# KM1M7CF15 register map
Vendor: Nuvoton Technology Corporation Japan; Series: KM1M7CF; File version: 1.0.3
CPU: CM7 r1p2, little endian, MPU, FPU, double-precision FPU, I-cache, D-cache, ITCM, DTCM, 4 interrupt priority bits
Registers are 32-bit, read-write, no defined reset value unless marked. A register's access mark holds for its fields unless they carry their own. Offsets are from the block's base; [hi:lo] are bit positions; {n}, {i} and the like mark numbered series.

## SYTM — Clock Generator
Base 0x40000000
0x00 SYS_PDID ro — Part Device ID Register
  [31:0] PDID — LSI product number ID
0x08 SYS_DID ro — Device ID Register
  [31:0] DID — Device ID
0x0C SYS_CID ro — Company ID Register
  [31:0] CID — Company ID
{0x10+4i} SYS_UID{i} ro (i=0..3) — U{i}ique ID n Register
  [31:0] UID — Uniqued data for each chip can be read.
{0x20+4i} SYS_UCID{i} ro (i=0..3) — U{i}ique Company ID n Register
  [31:0] UID — "0xFFFFFFFF" is always read out.
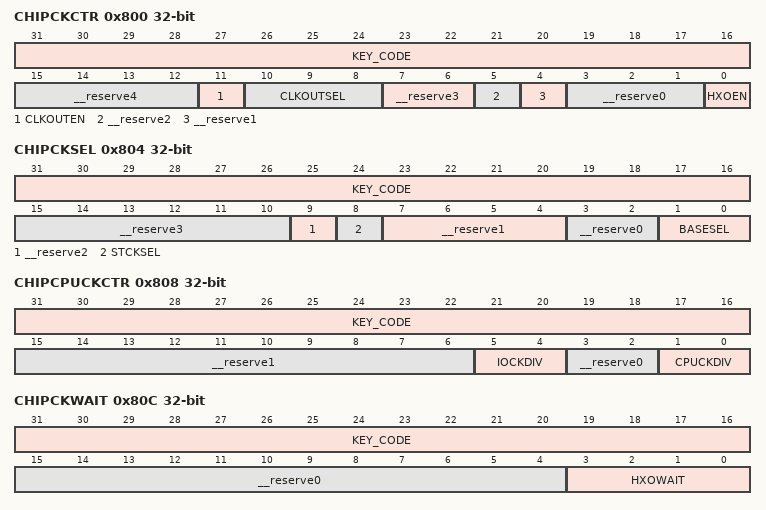
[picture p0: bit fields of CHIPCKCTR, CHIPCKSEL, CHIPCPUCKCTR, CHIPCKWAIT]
0x800 CHIPCKCTR access per field — Clock Control Register
  [31:16] KEY_CODE wo — Write enable code
  [15:12] __reserve4 rw — This bit must be set to "0".
  [11] CLKOUTEN rw — Internal clock output function
  [10:8] CLKOUTSEL rw — Output clock selection when the internal clock output function is enabled
  [7:6] __reserve3 rw — This bit must be set to "0".
  [5] __reserve2 ro — "0" is always read out.
  [4] __reserve1 rw — This bit must be set to "0".
  [3:1] __reserve0 rw — This bit must be set to "１".
  [0] HXOEN rw — External high-speed oscillation (HXO)
0x804 CHIPCKSEL access per field — Clock Selection Register
  [31:16] KEY_CODE wo — Write enable code
  [15:10] __reserve3 ro — "0" is always read out.
  [9] __reserve2 rw — This bit must be set to "0".
  [8] STCKSEL rw — Clock source selection for Systick
  [7:4] __reserve1 ro — "0" is always read out.
  [3:2] __reserve0 rw — This bit must be set to "0".
  [1:0] BASESEL rw — Clock source selection for the base clock (BASECLK)
0x808 CHIPCPUCKCTR access per field — CPU Clock Control Register
  [31:16] KEY_CODE wo — Write enable code
  [15:6] __reserve1 ro — "0" is always read out.
  [5:4] IOCKDIV rw — Setting of IOCLK division ratio for CPUCLK
  [3:2] __reserve0 ro — "0" is always read out.
  [1:0] CPUCKDIV rw — Setting of CPUCLK division ratio for BASECLK
0x80C CHIPCKWAIT access per field — Clock Oscillation Stabilization Wait Register
  [31:16] KEY_CODE wo — Write enable code
  [15:4] __reserve0 ro — "0" is always read out.
  [3:0] HXOWAIT rw — HXO oscillation stabilization wait cycle setting
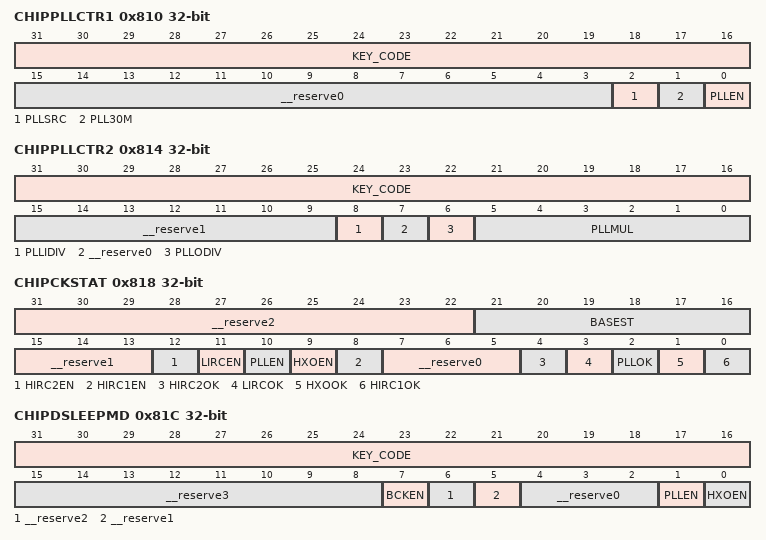
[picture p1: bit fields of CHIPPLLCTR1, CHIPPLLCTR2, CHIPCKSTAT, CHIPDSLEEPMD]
0x810 CHIPPLLCTR1 access per field — PLL Control Register 1
  [31:16] KEY_CODE wo — Write enable code
  [15:3] __reserve0 ro — "0" is always read out.
  [2] PLLSRC rw — Selection of the reference clock to be multiplied by PLL
  [1] PLL30M rw — PLL clock output control for Power Control PWM using High-Resolution output
  [0] PLLEN rw — PLL function
0x814 CHIPPLLCTR2 access per field — PLL Control Register 2
  [31:16] KEY_CODE wo — Write enable code
  [15:9] __reserve1 ro — "0" is always read out.
  [8] PLLIDIV rw — PLL input clock division ratio setting
  [7] __reserve0 ro — "0" is always read out.
  [6] PLLODIV rw — PLL output clock division ratio setting
  [5:0] PLLMUL rw — PLL multiplier value setting
0x818 CHIPCKSTAT ro — Clock Status Register
  [31:22] __reserve2 — "0" is always read out.
  [21:16] BASEST — State of each clock selection to BASECLK (0: not selected, 1: selected)
  [15:13] __reserve1 — "0" is always read out.
  [12] HIRC2EN — Internal high-speed oscillation 2 (HIRC2) state
  [11] LIRCEN — Internal low-speed oscillation (LIRC) state
  [10] PLLEN — PLL function state
  [9] HXOEN — External high-speed oscillation (HXO) state
  [8] HIRC1EN — Internal high-speed oscillation 1 (HIRC1) state
  [7:5] __reserve0 — "0" is always read out.
  [4] HIRC2OK — Internal high-speed oscillation 2 (HIRC2) stabilization status
  [3] LIRCOK — Internal low-speed oscillation (LIRC) stabilization status
  [2] PLLOK — PLL stabilization status
  [1] HXOOK — External high-speed oscillation (HXO) stabilization status
  [0] HIRC1OK — Internal high-speed oscillation 1(HIRC1) stabilization status
0x81C CHIPDSLEEPMD access per field — DEEPSLEEP Mode Control Register
  [31:16] KEY_CODE wo — Write enable code
  [15:8] __reserve3 ro — "0" is always read out.
  [7] BCKEN rw — Set BASECLK for DEEPSLEEP
  [6] __reserve2 ro — "0" is always read out.
  [5] __reserve1 rw — This bit must be set to "0".
  [4:2] __reserve0 ro — "1" is always read out.
  [1] PLLEN rw — Set PLL ON/OFF for DEEPSLEEP
  [0] HXOEN rw — Set external oscillation (HXO) ON/OFF for DEEPSLEEP
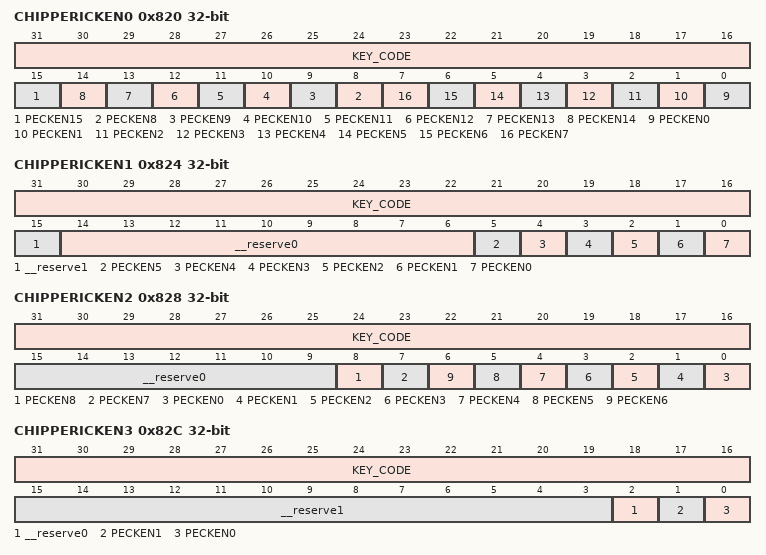
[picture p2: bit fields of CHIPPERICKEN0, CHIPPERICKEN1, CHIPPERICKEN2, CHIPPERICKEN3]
0x820 CHIPPERICKEN0 access per field — Peripheral Clock Enable Register 0
  [31:16] KEY_CODE wo — Write enable code
  [15] PECKEN15 rw — Clock supply to Multi Feedback Assist
  [n] PECKEN{n} rw (n=8..14) — Clock supply to Timer {2n-16} and {2n-15}
  [n] PECKEN{n} rw (n=0..7) — Clock supply to GPWM{n}
0x824 CHIPPERICKEN1 access per field — Peripheral Clock Enable Register 1
  [31:16] KEY_CODE wo — Write enable code
  [15] __reserve1 rw — This bit must be set to "0".
  [14:6] __reserve0 ro — "0" is always read out.
  [5] PECKEN5 rw — Clock supply to DMA controller
  [4] PECKEN4 rw — Clock supply to RTC
  [3] PECKEN3 rw — Clock supply to D/A Converter
  [2] PECKEN2 rw — Clock supply to A/D 2
  [1] PECKEN1 rw — Clock supply to A/D 1
  [0] PECKEN0 rw — Clock supply to A/D 0
0x828 CHIPPERICKEN2 access per field — Peripheral Clock Enable Register 2
  [31:16] KEY_CODE wo — Write enable code
  [15:9] __reserve0 ro — "0" is always read out.
  [8] PECKEN8 rw — Clock supply to CAN FD controller
  [7] PECKEN7 rw — Clock supply to SMBus/IIC Interface
  [n] PECKEN{n} rw (n=0..6) — Clock supply to serial interface {n}
0x82C CHIPPERICKEN3 access per field — Peripheral Clock Enable Register 3
  [31:16] KEY_CODE wo — Write enable code
  [15:3] __reserve1 ro — "0" is always read out.
  [2] __reserve0 rw — This bit must be set to "0".
  [1] PECKEN1 rw — Clock supply to CRYPTO
  [0] PECKEN0 rw — Clock supply to TRNG
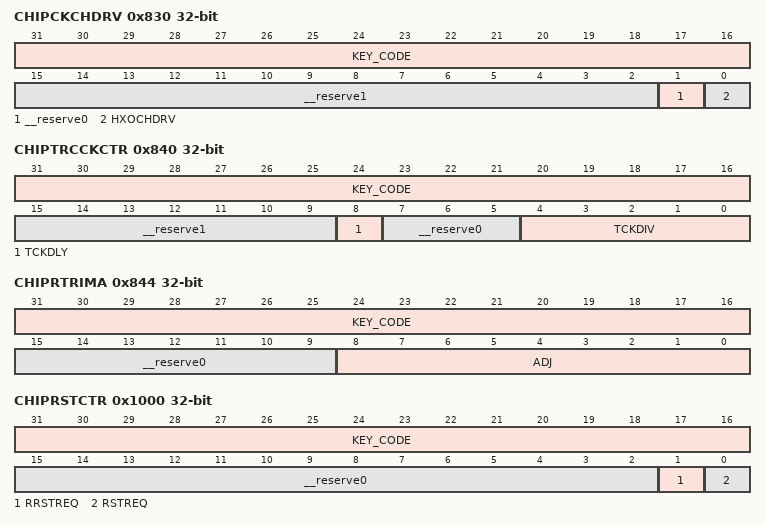
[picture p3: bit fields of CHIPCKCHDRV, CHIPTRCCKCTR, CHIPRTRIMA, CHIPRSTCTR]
0x830 CHIPCKCHDRV access per field — External Oscillation Capability Control Register
  [31:16] KEY_CODE wo — Write enable code
  [15:2] __reserve1 ro — "0" is always read out.
  [1] __reserve0 rw — This bit must be set to "0".
  [0] HXOCHDRV rw — High-speed external oscillation drive cabability
0x840 CHIPTRCCKCTR access per field — Trace Clock Control Register
  [31:16] KEY_CODE wo — Write enable code
  [15:9] __reserve1 ro — "0" is always read out.
  [8] TCKDLY rw — Trace data delay control
  [7:5] __reserve0 ro — "0" is always read out.
  [4:0] TCKDIV rw — Setting of trace clock division ratio for CPUCLK
0x844 CHIPRTRIMA access per field — Internal High-speed Oscillation 1 Frequency Triming Register
  [31:16] KEY_CODE wo — Write enable code
  [15:9] __reserve0 ro — "0" is always read out.
  [8:0] ADJ rw — Enter HIRC1 frequency correction value 2's complement (-256 to +255).
0x1000 CHIPRSTCTR access per field — Reset Control Register
  [31:16] KEY_CODE wo — Write enable code
  [15:2] __reserve0 ro — "0" is always read out.
  [1] RRSTREQ rw — Reserved-at-debug reset request
  [0] RSTREQ rw — System software reset request
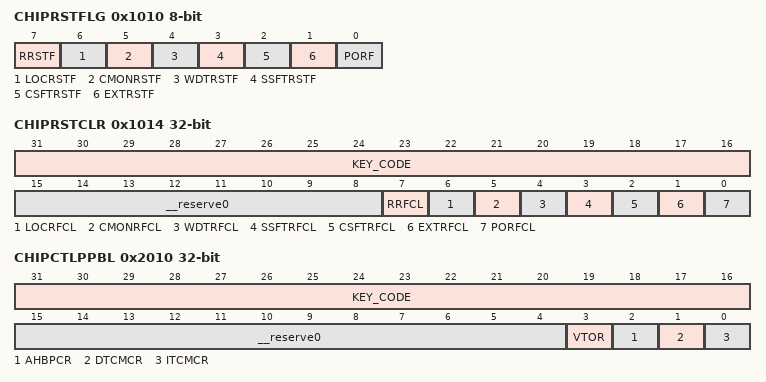
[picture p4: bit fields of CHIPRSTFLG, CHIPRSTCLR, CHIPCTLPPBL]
0x1010 CHIPRSTFLG 8-bit ro — Reset Flag Register
  [7] RRSTF — Reserved-at-debug reset flag
  [6] LOCRSTF — CPU LOCKUP reset flag
  [5] CMONRSTF — Clock error detection reset flag
  [4] WDTRSTF — WDT error detection reset flag
  [3] SSFTRSTF — System software reset flag
  [2] CSFTRSTF — CPU software reset flag
  [1] EXTRSTF — Pin reset flag
  [0] PORF — Power-on reset (POR) flag
0x1014 CHIPRSTCLR access per field — Reset Flag Clear Register
  [31:16] KEY_CODE wo — Write enable code
  [15:8] __reserve0 ro — "0" is always read out.
  [7] RRFCL wo — Clear CHIPRSTFLG.RRSTF by writing
  [6] LOCRFCL wo — Clear CHIPRSTFLG.LOCRSTF by writing
  [5] CMONRFCL wo — Clear CHIPRSTFLG.CMONRSTF by writing
  [4] WDTRFCL wo — Clear CHIPRSTFLG.WDTRSTF by writing
  [3] SSFTRFCL wo — Clear CHIPRSTFLG.SSFTRSTF by writing
  [2] CSFTRFCL wo — Clear CHIPRSTFLG.CSFTRSTF by writing
  [1] EXTRFCL wo — Clear CHIPRSTFLG.EXTRSTF by writing
  [0] PORFCL wo — Clear CHIPRSTFLG.PORF by writing
0x2010 CHIPCTLPPBL access per field — PPB Write Control Register
  [31:16] KEY_CODE wo — Write enable code
  [15:4] __reserve0 ro — "0" is always read out.
  [3] VTOR rw — VTOR write control
  [2] AHBPCR rw — AHBPCR write control
  [1] DTCMCR rw — DTCMCR write control
  [0] ITCMCR rw — ITCMCR write control
